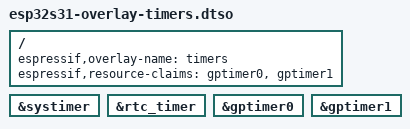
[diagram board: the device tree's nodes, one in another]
// SPDX-License-Identifier: GPL-2.0+
/dts-v1/;
/plugin/;

/ {
	espressif,overlay-name = "timers";
	espressif,resource-claims = "gptimer0", "gptimer1";
};

&systimer { status = "okay"; };
&rtc_timer { status = "okay"; };
&gptimer0 { status = "okay"; };
&gptimer1 { status = "okay"; };
